# RA register map
Vendor: Renesas; Series: All Chips; File version: x.xx
Registers are 32-bit, read-write, reset 0x0 unless marked. A register's access mark holds for its fields unless they carry their own. Offsets are from the block's base; [hi:lo] are bit positions; {n}, {i} and the like mark numbered series; 'fields as' and 'values as' point back to an identical list.

## R_DEBUG — Debug Function
Base 0x4001B000
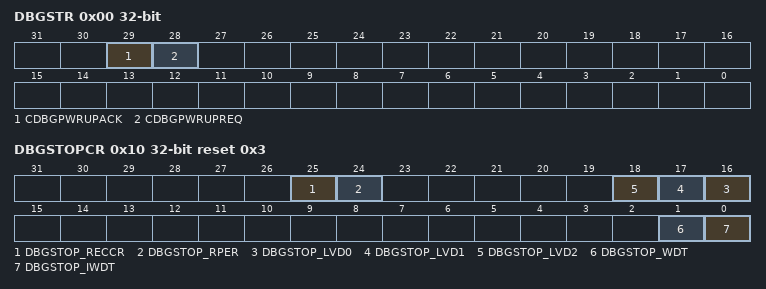
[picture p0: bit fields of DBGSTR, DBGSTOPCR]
0x00 DBGSTR ro — Debug Status Register
  [29] CDBGPWRUPACK — Debug power-up acknowledge
    0=Debug power-up request is not acknowledged; 1=Debug power-up request is acknowledged
  [28] CDBGPWRUPREQ — Debug power-up request
    0=0: OCD is not requesting debug power up; 1=0: OCD is requesting debug power up
0x10 DBGSTOPCR reset 0x3 — Debug Stop Control Register
  [25] DBGSTOP_RECCR — Mask bit for SRAM ECC error
  [24] DBGSTOP_RPER — Mask bit for SRAM parity error
  [n+16] DBGSTOP_LVD{n} (n=0..2) — Mask bit for LVD reset/interupt
    0=Enable reset/interupt on corresponding LVD; 1=Mask reset/interupt on corresponding LVD
  [1] DBGSTOP_WDT — Mask bit for WDT reset/interrupt
  [0] DBGSTOP_IWDT — Mask bit for IWDT reset/interrupt

## R_DMA — DMA Controller Common
Base 0x40005200
0x00 DMAST 8-bit — DMAC Module Activation Register
  [0] DMST — DMAC Operation Enable
    0=Disabled; 1=Enabled

## R_DMAC0 — DMA Controller
Base 0x40005000
Same registers: R_DMAC1 0x40005040, R_DMAC2 0x40005080, R_DMAC3 0x400050C0, R_DMAC4 0x40005100, R_DMAC5 0x40005140, R_DMAC6 0x40005180, R_DMAC7 0x400051C0
0x00 DMSAR — DMA Source Address Register
  [31:0] DMSAR — Specifies the transfer source start address.
0x04 DMDAR — DMA Destination Address Register
  [31:0] DMDAR — Specifies the transfer destination start address.
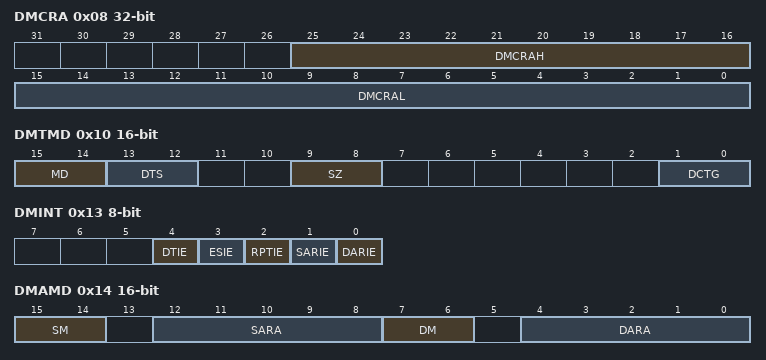
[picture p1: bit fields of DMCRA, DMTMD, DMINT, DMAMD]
0x08 DMCRA — DMA Transfer Count Register
  [25:16] DMCRAH — Upper bits of transfer count
  [15:0] DMCRAL — Lower bits of transfer count
0x0C DMCRB 16-bit — DMA Block Transfer Count Register
  [15:0] DMCRB — Specifies the number of block transfer operations or repeat transfer operations.
    0=65,536 blocks; other=others (DMCRB blocks)
0x10 DMTMD 16-bit — DMA Transfer Mode Register
  [15:14] MD — Transfer Mode Select
    0=Normal transfer; 1=Repeat transfer; 2=Block transfer; 3=Setting prohibited
  [13:12] DTS — Repeat Area Select
    0=The destination is specified as the repeat area or block area; 1=The source is specified as the repeat area or block area; 2=The repeat area or block area is not specified; 3=Setting prohibited
  [9:8] SZ — Transfer Data Size Select
    0=8 bits; 1=16 bits; 2=32 bits; 3=Setting prohibited
  [1:0] DCTG — Transfer Request Source Select
    0=Software; 1=Interrupts*1 from peripheral modules or external interrupt input pins; 2=Setting prohibited; 3=Setting prohibited
0x13 DMINT 8-bit — DMA Interrupt Setting Register
  [all] fields
    0=Disabled; 1=Enabled
  [4] DTIE — Transfer End Interrupt Enable
  [3] ESIE — Transfer Escape End Interrupt Enable
  [2] RPTIE — Repeat Size End Interrupt Enable
  [1] SARIE — Source Address Extended Repeat Area Overflow Interrupt Enable
  [0] DARIE — Destination Address Extended Repeat Area Overflow Interrupt Enable
0x14 DMAMD 16-bit — DMA Address Mode Register
  [15:14] SM — Source Address Update Mode
    0=Fixed address; 1=Offset addition; 2=Incremented address; 3=Decremented address
  [12:8] SARA — Source Address Extended Repeat Area Specifies the extended repeat area on the source address. For details on the settings.
  [7:6] DM — Destination Address Update Mode
    values as SM
  [4:0] DARA — Destination Address Extended Repeat Area Specifies the extended repeat area on the destination address. For details on the settings.
0x18 DMOFR — DMA Offset Register
  [31:0] DMOFR — Specifies the offset when offset addition is selected as the address update mode for transfer source or destination.
0x1C DMCNT 8-bit — DMA Transfer Enable Register
  [0] DTE read-modifies — DMA Transfer Enable
    0=Disabled; 1=Enabled
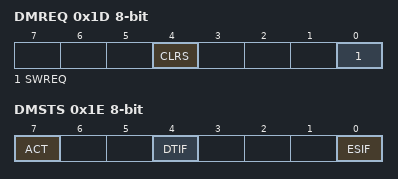
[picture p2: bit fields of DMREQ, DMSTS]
0x1D DMREQ 8-bit — DMA Software Start Register
  [4] CLRS — DMA Software Start Bit Auto Clear Select
    0=SWREQ bit is cleared after DMA transfer is started by software; 1=SWREQ bit is not cleared after DMA transfer is started by software
  [0] SWREQ read-modifies — DMA Software Start
    0=DMA transfer is not requested; 1=DMA transfer is requested
0x1E DMSTS 8-bit — DMA Status Register
  [7] ACT ro — DMA Active Flag
    0=DMAC operation suspended; 1=DMAC operating
  [4] DTIF write-0-clears read-modifies — Transfer End Interrupt Flag
    0=No interrupt; 1=Interrupt occurred
  [0] ESIF write-0-clears read-modifies — Transfer Escape End Interrupt Flag
    0=No interrupt; 1=Interrupt occurred
